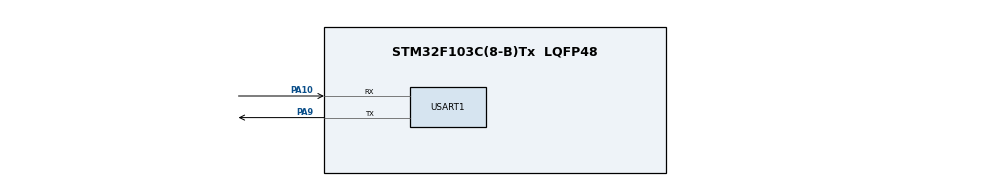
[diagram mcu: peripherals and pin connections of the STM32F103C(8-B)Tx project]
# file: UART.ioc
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Mcu.Family=STM32F1
Mcu.Name=STM32F103C(8-B)Tx
Mcu.Package=LQFP48
NVIC.PriorityGroup=NVIC_PRIORITYGROUP_4
NVIC.USART1_IRQn=true\:0\:0\:false\:false\:true\:true\:true
PA10.Mode=Asynchronous
PA10.Signal=USART1_RX
PA13.Mode=Serial_Wire
PA13.Signal=SYS_JTMS-SWDIO
PA14.Mode=Serial_Wire
PA14.Signal=SYS_JTCK-SWCLK
PA9.Mode=Asynchronous
PA9.Signal=USART1_TX
ProjectManager.HeapSize=0x200
ProjectManager.StackSize=0x400
ProjectManager.TargetToolchain=SW4STM32
RCC.APB1Freq_Value=8000000
RCC.APB2Freq_Value=8000000
USART1.VirtualMode=VM_ASYNC
board=custom

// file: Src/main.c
/* USER CODE BEGIN Header */
/**
  ******************************************************************************
  * @file           : main.c
  * @brief          : Main program body
  ******************************************************************************
  * @attention
  *
  * <h2><center>&copy; Copyright (c) 2020 STMicroelectronics.
  * All rights reserved.</center></h2>
  *
  * This software component is licensed by ST under BSD 3-Clause license,
  * the "License"; You may not use this file except in compliance with the
  * License. You may obtain a copy of the License at:
  *                        opensource.org/licenses/BSD-3-Clause
  *
  ******************************************************************************
  */
/* USER CODE END Header */

#include "main.h"
#include "stdio.h"

UART_HandleTypeDef huart1;

/* USER CODE BEGIN PV */
int i;    //khai bao bien dem
char buffer[100];   //khai bao mang buffer gom 100 phan tu
int length;    //khao bao bien length tuong ung voi chieu dai
char Rx_indx, Rx_data[2], Rx_Buffer[100], Transfer_cplt;    //khai bao cac bien de nhan du lieu
/* USER CODE END PV */

void SystemClock_Config(void);
static void MX_GPIO_Init(void);
static void MX_USART1_UART_Init(void);
/* USER CODE BEGIN PFP */
#ifdef __GNUC__
/* With GCC/RAISONANCE, small printf (option LD Linker -> Libraries -> small
     printf set to 'Yes') calls __io_putchar()  */
  #define PUTCHAR_PROTOTYPE int __io_putchar(int ch)
#else
  #define PUTCHAR_PROTOTYPE int fputc(int ch, FILE *f)
  #define GETCHAR_PROTOTYpE int fgetc(FILE *f);
#endif  /*  __GNUC__  */
	PUTCHAR_PROTOTYPE
{
	/* Place your implementation of fputc here */
	/* e.g. write a character to the UART */
	HAL_UART_Transmit(&huart1, (uint8_t*)&ch, 1, 100);
	/* Loop intil the end of transmittion */

	return ch;
}

//Ham ngat UART
void HAL_UART_RxCpltCallback(UART_HandleTypeDef *huart)
{
	uint8_t i;
	if(huart->Instance == USART1)
	{
		if(Rx_indx==0)  {for(i=0; i<100; i++) Rx_Buffer[i]=0;}    //Xoa Rx_Buffer truoc khi nhan du lieu
		if(Rx_data[0]!=13)    //Neu du lieu nhan duoc khac voi 13 (13 la ma cua phim enter)
		{
			Rx_Buffer[Rx_indx++]=Rx_data[0];    //them du lieu vao Rx_Buffer
		}
		else    //Neu phim enter duoc nhan
		{
			Rx_indx=0;    //Dua Rx_indx ve 0
			Transfer_cplt = 1;    //Qua trinh truyen hoan tat, du lieu da san sang de doc
		}
		HAL_UART_Receive_IT(&huart1, Rx_data, 1);    //kich hoat uart nhan du lieu ngat moi luc
	}
}

/* USER CODE END PFP */

int main(void)
{

  /* MCU Configuration--------------------------------------------------------*/

  /* Reset of all peripherals, Initializes the Flash interface and the Systick. */
  HAL_Init();

  /* Configure the system clock */
  SystemClock_Config();

  /* Initialize all configured peripherals */
  MX_GPIO_Init();
  MX_USART1_UART_Init();
  /* USER CODE BEGIN 2 */
  HAL_UART_Receive_IT(&huart1, Rx_data, 1);    //kich hoat ngat uart khi nhan duoc 1 byte

  /* USER CODE END 2 */

  /* Infinite loop */
  while (1)
  {

    /* USER CODE BEGIN 3 */

//	  printf("Hello\r \n");
//	  printf("Gia tri cua i: %d \r\n", i);
//	  HAL_Delay(500);
//	  i++;

//	  //Gio khong dung printf nua ma thay vao do su dung sprintf
//	  sprintf(buffer, "Xin chao cac dong chi! :) \r\n");
//	  length = strlen(buffer);
//	  HAL_UART_Transmit(&huart1, buffer, length, 1000);    //truyen du lieu tren uart, du lieu o day la buffer co chieu dai la length
//	  HAL_Delay(500);

	  if(Transfer_cplt)
	  {
		  sprintf(buffer, "%s\r\n", Rx_Buffer);
		  length = strlen(buffer);
		  HAL_UART_Transmit(&huart1, buffer, length, 1000);
		  Transfer_cplt = 0;    //Reset lai bien Transfer_complete
		  HAL_Delay(500);
	  }
  }
  /* USER CODE END 3 */
}

void SystemClock_Config(void)
{
  RCC_OscInitTypeDef RCC_OscInitStruct = {0};
  RCC_ClkInitTypeDef RCC_ClkInitStruct = {0};

  /** Initializes the CPU, AHB and APB busses clocks
  */
  RCC_OscInitStruct.OscillatorType = RCC_OSCILLATORTYPE_HSI;
  RCC_OscInitStruct.HSIState = RCC_HSI_ON;
  RCC_OscInitStruct.HSICalibrationValue = RCC_HSICALIBRATION_DEFAULT;
  RCC_OscInitStruct.PLL.PLLState = RCC_PLL_NONE;
  if (HAL_RCC_OscConfig(&RCC_OscInitStruct) != HAL_OK)
  {
    Error_Handler();
  }
  /** Initializes the CPU, AHB and APB busses clocks
  */
  RCC_ClkInitStruct.ClockType = RCC_CLOCKTYPE_HCLK|RCC_CLOCKTYPE_SYSCLK
                              |RCC_CLOCKTYPE_PCLK1|RCC_CLOCKTYPE_PCLK2;
  RCC_ClkInitStruct.SYSCLKSource = RCC_SYSCLKSOURCE_HSI;
  RCC_ClkInitStruct.AHBCLKDivider = RCC_SYSCLK_DIV1;
  RCC_ClkInitStruct.APB1CLKDivider = RCC_HCLK_DIV1;
  RCC_ClkInitStruct.APB2CLKDivider = RCC_HCLK_DIV1;

  if (HAL_RCC_ClockConfig(&RCC_ClkInitStruct, FLASH_LATENCY_0) != HAL_OK)
  {
    Error_Handler();
  }
}

static void MX_USART1_UART_Init(void)
{

  huart1.Instance = USART1;
  huart1.Init.BaudRate = 115200;
  huart1.Init.WordLength = UART_WORDLENGTH_8B;
  huart1.Init.StopBits = UART_STOPBITS_1;
  huart1.Init.Parity = UART_PARITY_NONE;
  huart1.Init.Mode = UART_MODE_TX_RX;
  huart1.Init.HwFlowCtl = UART_HWCONTROL_NONE;
  huart1.Init.OverSampling = UART_OVERSAMPLING_16;
  if (HAL_UART_Init(&huart1) != HAL_OK)
  {
    Error_Handler();
  }

}

static void MX_GPIO_Init(void)
{

  /* GPIO Ports Clock Enable */
  __HAL_RCC_GPIOA_CLK_ENABLE();

}

void Error_Handler(void)
{
}

/************************ (C) COPYRIGHT STMicroelectronics *****END OF FILE****/
